# AT90USB162 device description
Architecture: AVR8; Family: megaAVR
Registers are 8-bit, access not given, no defined reset value unless marked. A register's access mark holds for its fields unless they carry their own. Offsets are from the block's base; [hi:lo] are bit positions.

## PORTB — I/O Port
Instances: PORTB 0x00
0x23 PINB — Port B Input Pins
0x24 DDRB — Port B Data Direction Register
0x25 PORTB — Port B Data Register

## PORTD — I/O Port
Instances: PORTD 0x00
0x29 PIND — Port D Input Pins
0x2A DDRD — Port D Data Direction Register
0x2B PORTD — Port D Data Register

## PORTC — I/O Port
Instances: PORTC 0x00
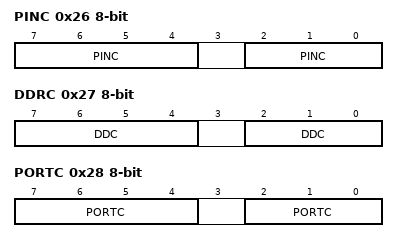
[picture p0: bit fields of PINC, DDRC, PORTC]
0x26 PINC — Port C Input Pins
  [7:4] PINC (bit 4 of the value upward) — Port C Input Pins bits
  [2:0] PINC — Port C Input Pins bits
0x27 DDRC — Port C Data Direction Register
  [7:4] DDC (bit 4 of the value upward) — Port C Data Direction Register bits
  [2:0] DDC — Port C Data Direction Register bits
0x28 PORTC — Port C Data Register
  [7:4] PORTC (bit 4 of the value upward) — Port C Data Register bits
  [2:0] PORTC — Port C Data Register bits

## SPI — Serial Peripheral Interface
Instances: SPI 0x00
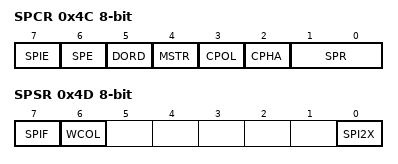
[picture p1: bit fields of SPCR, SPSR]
0x4C SPCR — SPI Control Register
  [7] SPIE — SPI Interrupt Enable
  [6] SPE — SPI Enable
  [5] DORD — Data Order
  [4] MSTR — Master/Slave Select
  [3] CPOL — Clock polarity
  [2] CPHA — Clock Phase
  [1:0] SPR — SPI Clock Rate Selects
    0=fosc/4; 1=fosc/16; 2=fosc/64; 3=fosc/128; 4=fosc/2; 5=fosc/8; 6=fosc/32; 7=fosc/64
0x4D SPSR — SPI Status Register
  [7] SPIF — SPI Interrupt Flag
  [6] WCOL — Write Collision Flag
  [0] SPI2X — Double SPI Speed Bit
0x4E SPDR — SPI Data Register

## BOOT_LOAD — Bootloader
Instances: BOOT_LOAD 0x00
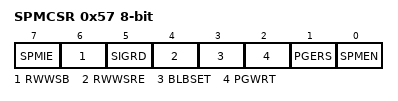
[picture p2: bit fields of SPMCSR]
0x57 SPMCSR — Store Program Memory Control Register
  [7] SPMIE — SPM Interrupt Enable
  [6] RWWSB — Read While Write Section Busy
  [5] SIGRD — Signature Row Read
  [4] RWWSRE — Read While Write section read enable
  [3] BLBSET — Boot Lock Bit Set
  [2] PGWRT — Page Write
  [1] PGERS — Page Erase
  [0] SPMEN — Store Program Memory Enable

## EEPROM
Instances: EEPROM 0x00
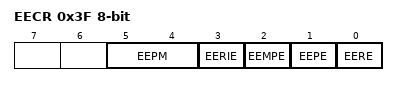
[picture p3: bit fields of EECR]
0x3F EECR — EEPROM Control Register
  [5:4] EEPM — EEPROM Programming Mode Bits
    0=Erase and Write in one operation; 1=Erase Only; 2=Write Only
  [3] EERIE — EEPROM Ready Interrupt Enable
  [2] EEMPE — EEPROM Master Write Enable
  [1] EEPE — EEPROM Write Enable
  [0] EERE — EEPROM Read Enable
0x40 EEDR — EEPROM Data Register
0x41 EEAR 16-bit bits used 11:0 — EEPROM Address Register Low Bytes

## TC0 (TC8 module) — Timer/Counter, 8-bit
Instances: TC0 0x00
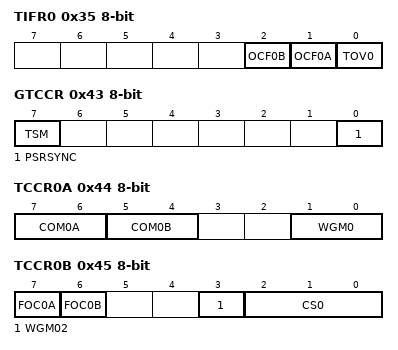
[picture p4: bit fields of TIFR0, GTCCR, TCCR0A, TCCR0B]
0x35 TIFR0 — Timer/Counter0 Interrupt Flag register
  [2] OCF0B — Timer/Counter0 Output Compare Flag 0B
  [1] OCF0A — Timer/Counter0 Output Compare Flag 0A
  [0] TOV0 — Timer/Counter0 Overflow Flag
0x43 GTCCR — General Timer/Counter Control Register
  [7] TSM — Timer/Counter Synchronization Mode
  [0] PSRSYNC — Prescaler Reset Timer/Counter1 and Timer/Counter0
0x44 TCCR0A — Timer/Counter Control Register A
  [7:6] COM0A — Compare Output Mode, Phase Correct PWM Mode
  [5:4] COM0B — Compare Output Mode, Fast PWm
  [1:0] WGM0 — Waveform Generation Mode
0x45 TCCR0B — Timer/Counter Control Register B
  [7] FOC0A — Force Output Compare A
  [6] FOC0B — Force Output Compare B
  [3] WGM02
  [2:0] CS0 — Clock Select
    0=No Clock Source (Stopped); 1=Running, No Prescaling; 2=Running, CLK/8; 3=Running, CLK/64; 4=Running, CLK/256; 5=Running, CLK/1024; 6=Running, ExtClk Tx Falling Edge; 7=Running, ExtClk Tx Rising Edge
0x46 TCNT0 — Timer/Counter0
0x47 OCR0A — Timer/Counter0 Output Compare Register
0x48 OCR0B — Timer/Counter0 Output Compare Register
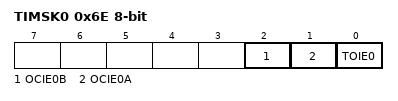
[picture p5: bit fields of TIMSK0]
0x6E TIMSK0 — Timer/Counter0 Interrupt Mask Register
  [2] OCIE0B — Timer/Counter0 Output Compare Match B Interrupt Enable
  [1] OCIE0A — Timer/Counter0 Output Compare Match A Interrupt Enable
  [0] TOIE0 — Timer/Counter0 Overflow Interrupt Enable

## TC1 (TC16 module) — Timer/Counter, 16-bit
Instances: TC1 0x00
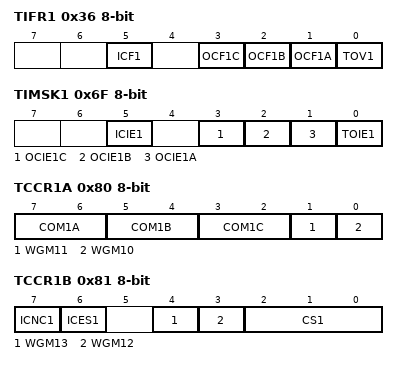
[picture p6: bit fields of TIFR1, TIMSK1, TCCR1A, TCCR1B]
0x36 TIFR1 — Timer/Counter1 Interrupt Flag register
  [5] ICF1 — Input Capture Flag 1
  [3] OCF1C — Output Compare Flag 1C
  [2] OCF1B — Output Compare Flag 1B
  [1] OCF1A — Output Compare Flag 1A
  [0] TOV1 — Timer/Counter1 Overflow Flag
0x6F TIMSK1 — Timer/Counter1 Interrupt Mask Register
  [5] ICIE1 — Timer/Counter1 Input Capture Interrupt Enable
  [3] OCIE1C — Timer/Counter1 Output Compare C Match Interrupt Enable
  [2] OCIE1B — Timer/Counter1 Output Compare B Match Interrupt Enable
  [1] OCIE1A — Timer/Counter1 Output Compare A Match Interrupt Enable
  [0] TOIE1 — Timer/Counter1 Overflow Interrupt Enable
0x80 TCCR1A — Timer/Counter1 Control Register A
  [7:6] COM1A — Compare Output Mode 1A, bits
  [5:4] COM1B — Compare Output Mode 1B, bits
  [3:2] COM1C — Compare Output Mode 1C, bits
  [1] WGM11 — Waveform Generation Mode
  [0] WGM10 — Waveform Generation Mode
0x81 TCCR1B — Timer/Counter1 Control Register B
  [7] ICNC1 — Input Capture 1 Noise Canceler
  [6] ICES1 — Input Capture 1 Edge Select
  [4] WGM13 (bit 2 of the value upward) — Waveform Generation Mode
  [3] WGM12 (bit 2 of the value upward) — Waveform Generation Mode
  [2:0] CS1 — Prescaler source of Timer/Counter 1
    0=No Clock Source (Stopped); 1=Running, No Prescaling; 2=Running, CLK/8; 3=Running, CLK/64; 4=Running, CLK/256; 5=Running, CLK/1024; 6=Running, ExtClk Tx Falling Edge; 7=Running, ExtClk Tx Rising Edge
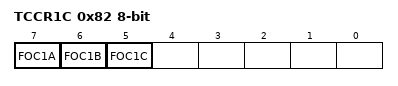
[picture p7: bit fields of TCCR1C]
0x82 TCCR1C — Timer/Counter 1 Control Register C
  [7] FOC1A — Force Output Compare 1A
  [6] FOC1B — Force Output Compare 1B
  [5] FOC1C — Force Output Compare 1C
0x84 TCNT1 16-bit — Timer/Counter1 Bytes
0x86 ICR1 16-bit — Timer/Counter1 Input Capture Register Bytes
0x88 OCR1A 16-bit — Timer/Counter1 Output Compare Register A Bytes
0x8A OCR1B 16-bit — Timer/Counter1 Output Compare Register B Bytes
0x8C OCR1C 16-bit — Timer/Counter1 Output Compare Register C Bytes
